# ATtiny10 device description
Architecture: AVR8L; Family: tinyAVR
Programming and debug interfaces: TPI
Registers are 8-bit, access not given, no defined reset value unless marked. A register's access mark holds for its fields unless they carry their own. Offsets are from the block's base; lines under a group give offsets from that group; [hi:lo] are bit positions; {n}, {i} and the like mark numbered series; 'fields as' and 'values as' point back to an identical list; <NAME> marks a mode.

## Ordering variants
ATtiny10-TSHR: SOT23-6, pinout SOT23_6, up to 12 MHz, -40 to 85 C, 1.8 to 5.5 V
ATtiny10-MAHR: UDFN8, up to 12 MHz, -40 to 85 C, 1.8 to 5.5 V
ATtiny10-TS8R: SOT23-6, pinout SOT23_6, up to 10 MHz, -40 to 125 C, 1.8 to 5.5 V

## Memory
prog space: start 0x0000 size 0x0400, little endian
  0x0000 FLASH size 0x0400 flash, rw, executable, page 0x80
signatures space: start 0 size 3, little endian
  0 SIGNATURES size 3 signatures, ro
fuses space: start 0 size 0x0001, little endian
  0 FUSES size 0x0001 fuses, rw
lockbits space: start 0 size 0x0001, little endian
  0 LOCKBITS size 0x0001 lockbits, rw
data space: start 0x0000 size 0x4400, little endian
  0x0000 IO size 0x40 io
  0x0040 SRAM size 0x20 ram
  0x3F00 MAPPED_NVM_LOCK_BITS size 0x0002 sysreg
  0x3F40 MAPPED_CONFIGURATION_BITS size 0x0002 sysreg
  0x3F80 MAPPED_CALIBRATION_BITS size 0x0002 sysreg
  0x3FC0 MAPPED_DEVICE_ID_BITS size 0x0004 sysreg
  0x4000 MAPPED_FLASH size 0x0400 flash

## Peripheral instances (address, pins/pin function, parameters)
ADC at 0x00 — Analog-to-Digital Converter
  pins: ADC0 PB0; ADC1 PB1; ADC2 PB2; ADC3 PB3
AC at 0x00 — Analog Comparator
  pins: AIN0 PB0; AIN1 PB1
CPU at 0x00 — CPU Registers
  parameters: CORE_VERSION=AVR8L_0
PORTB at 0x00 — I/O Port
  pins: P0 PB0; P1 PB1; P2 PB2; P3 PB3
EXINT at 0x00 — External Interrupts
  pins: PCINT0 PB0; PCINT1 PB1; PCINT2 PB2; PCINT3 PB3; INT0 PB2
TC0 at 0x00 — Timer/Counter, 16-bit
  pins: OCA PB0; OCB PB1; T PB2
WDT at 0x00 — Watchdog Timer
FUSE at 0 in fuses — Fuses
LOCKBIT at 0 in lockbits — Lockbits

## Interrupts
0 RESET — External Reset, Power-on Reset and Watchdog Reset
1 INT0 — External Interrupt Request 0
2 PCINT0 — Pin Change Interrupt Request 0
3 TIM0_CAPT — Timer/Counter0 Input Capture
4 TIM0_OVF — Timer/Counter0 Overflow
5 TIM0_COMPA — Timer/Counter Compare Match A
6 TIM0_COMPB — Timer/Counter Compare Match B
7 ANA_COMP — Analog Comparator
8 WDT — Watchdog Time-out
9 VLM — Vcc Voltage Level Monitor
10 ADC — ADC Conversion Complete

## Properties
SIGNATURES: SIGNATURE0=0x1e, SIGNATURE1=0x90, SIGNATURE2=0x03

## Pinouts (pin number, pad)
SOT23_6: 1 PB0, 2 GND, 3 PB1, 4 PB2, 5 VCC, 6 PB3
UDFN8: 1 PB1, 4 GND, 5 PB0, 6 PB3, 7 VCC, 8 PB2

## FUSE — Fuses
Instances: FUSE 0 in fuses
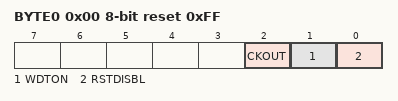
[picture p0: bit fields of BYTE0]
0x00 BYTE0 reset 0xFF
  [2] CKOUT — Output external clock
  [1] WDTON — Watch dog timer always on
  [0] RSTDISBL — Disable external reset

## LOCKBIT — Lockbits
Instances: LOCKBIT 0 in lockbits
0x00 LOCKBIT reset 0xFF
  [1:0] LB — Memory Lock
    0=PROG_VER_DISABLED (Further programming and verification disabled); 2=PROG_DISABLED (Further programming disabled); 3=NO_LOCK (No memory lock features enabled)

## ADC — Analog-to-Digital Converter
Instances: ADC 0x00
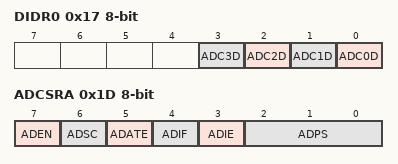
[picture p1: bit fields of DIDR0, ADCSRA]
0x17 DIDR0 — Digital Input Disable Register
  [n] ADC{n}D (n=0..3)
0x19 ADCL — ADC Data Register
0x1B ADMUX — The ADC multiplexer Selection Register
  [1:0] MUX — Analog Channel Selection Bits
0x1C ADCSRB — The ADC Control and Status register B
  [2:0] ADTS — ADC Auto Trigger Source bits
    0=FREE_RUNNING_MODE; 1=ANALOG_COMPARATOR; 2=EXTERNAL_INTERRUPT_REQUEST_0; 3=TIMER_COUNTER0_COMPARE_MATCH_A; 4=TIMER_COUNTER0_OVERFLOW; 5=TIMER_COUNTER0_COMPARE_MATCH_B; 6=PIN_CHANGE_INTERRUPT_0_REQUEST; 7=TIMER_COUNTER0_CAPTURE_EVENT
0x1D ADCSRA — The ADC Control and Status register A
  [7] ADEN — ADC Enable
  [6] ADSC — ADC Start Conversion
  [5] ADATE — ADC Auto Trigger Enable
  [4] ADIF — ADC Interrupt Flag
  [3] ADIE — ADC Interrupt Enable
  [2:0] ADPS — ADC Prescaler Select Bits
    0=2; 1=2; 2=4; 3=8; 4=16; 5=32; 6=64; 7=128
